# nrf7140_wificore register map
Vendor: Nordic Semiconductor; Series: nRF71; File version: 1
Registers are 32-bit, read-write, reset 0x0 unless marked. A register's access mark holds for its fields unless they carry their own. Offsets are from the block's base; [hi:lo] are bit positions; lines under a group give offsets from that group; {n}, {i} and the like mark numbered series.

## RPUPHY (part 4 of 8) — WIFICore RPU PHY peripherals
Base 0x48080000; alternate view of RPUMAC
0xA000 WLAN_AGC group — Unspecified
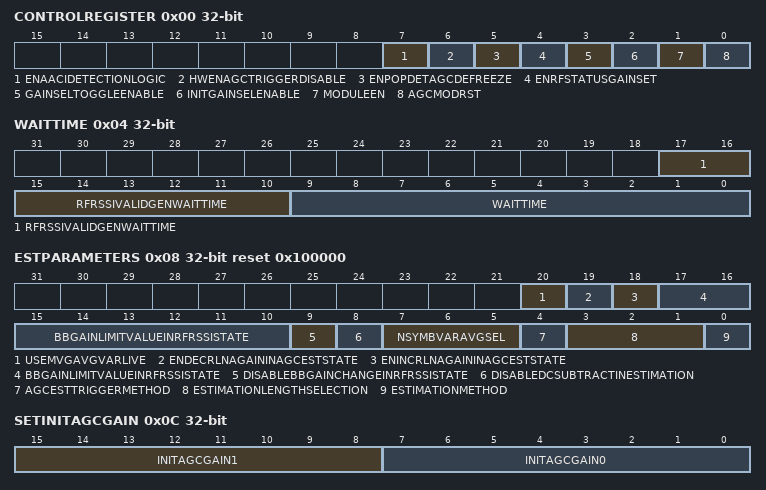
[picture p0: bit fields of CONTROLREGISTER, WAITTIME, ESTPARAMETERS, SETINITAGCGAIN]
  0x00 CONTROLREGISTER — WLAN AGC CONTROL REGISTER
    [7] ENAACIDETECTIONLOGIC — If Flag sets to 1, enables the AACI detection logic. '0' - AACI detection logic is disabled.
    [6] HWENAGCTRIGGERDISABLE — To assert AGC_TRIGGER_DISABLE through ED hardware. When ED is done then immediately AGC module is frozen to stop any further AGC updates. AGC module is released when ED module is reset.
    [5] ENPOPDETAGCDEFREEZE — If Flag set to 1, then it allows to clear the AGC Trigger Disable flag when POP Event comes
    [4] ENRFSTATUSGAINSET — Bit to enable Gain Changes due to RF RSSI STATUS.1-Enable0-Disable
    [3] GAINSELTOGGLEENABLE — Bit to enable registering of changes in Gain Selection.0-Disable1-Enable
    [2] INITGAINSELENABLE — Bit to enable initial AGC gain selection.01
    [1] MODULEEN — Bit field to enable AGC module. 1-enable, 0-disable
    [0] AGCMODRST — Bit to reset the AGC process.
  0x04 WAITTIME — WLAN AGC WAIT TIME
    [17:10] RFRSSIVALIDGENWAITTIME — This value indicates the number of valid samples we need to wait( for the settling of LNA ) to regenerate and read RF RSSI valid.the RSSI valid will be used in RF RSSI STATUS state in AGC fsm.
    [9:0] WAITTIME — The number of cycles after which the final enable will be given to the module once the module enable is asserted high.
  0x08 ESTPARAMETERS reset 0x100000 — WLAN AGC EST PARAMETERS
    [20] USEMVGAVGVARLIVE — This bit when made '1' will enable the moving averager which averages the latest N values of individual variance estimates and also connect the corresponding dB value to the AGC live variance output ports and status registers. The port output will be used by the ED module for ACI detection.When this bit is '0', the moving averager is disabled and the variance estimate is sent out as live variance on the ports and status registers.
    [19] ENDECRLNAGAININAGCESTSTATE — This bit set to '1' will enable the logic that generates DECR request to LNA gain controller. '0' will disable the generation of DECR. This is applicable to both internal 3-bit RF RSSI LNA gain control mode and SLGC mode.
    [18] ENINCRLNAGAININAGCESTSTATE — This bit set to '1' will enable the logic that generates INCR request to LNA gain controller. '0' will disable the generation of INCR. This is applicable to both internal 3-bit RF RSSI LNA gain control mode and SLGC mode.
    [17:10] BBGAINLIMITVALUEINRFRSSISTATE — This value is used to limit the allowed base band gain increment, when LNA gain is reduced ( stage changed )in RF RSSI STATE due to compression signal.
    [9] DISABLEBBGAINCHANGEINRFRSSISTATE — This bit is used either to allow or disallow the base band gain increment, when LNA gain is reduced ( stage changed )in RF RSSI STATE due to compression signal.
    [8] DISABLEDCSUBTRACTINESTIMATION — Flag to disable or enable DC subtraction ( | E[X] |^2 ) while estimating the variance which is used to compute the gain.
    [7:5] NSYMBVARAVGSEL — Number of symbol over which variance is averaged to use in AGC trigger condition:0: 1 symbol1: 2 symbols2: 4 symbols3: 8 symbols4: 16 symbolsEach symbol constitutes number of samples defined in (ESTIMATION_LENGTH_SELECTION)
    [4] AGCESTTRIGGERMETHOD — Defines trigger method used in AGC:
      0=AGC estimation process starts only after ED Done; 1=AGC is free running and starts adjusting the gain value if the absolute difference in RSSI (variance) and target value is not within the limits of lower and upper threshold or if clip count is more than certain threshold
    [3:1] ESTIMATIONLENGTHSELECTION — Estimation window length selection0-8samples,1-16 samples,2-32 samples, 3-64 samples, 4-128 samples, 5-256samples, 6-512 samples
    [0] ESTIMATIONMETHOD — 0: Variance based estimation, 1: Peak based estimation
  0x0C SETINITAGCGAIN — WLAN AGC SET INIT AGC GAIN
    [15:8] INITAGCGAIN1 — 2's complement of the value is considered for this field. So the range is from -128 to 127dB.
    [7:0] INITAGCGAIN0 — Register for setting the initial AGC gain.2's complement of the value is considered for the field. So the range is from -128 to 127dB.
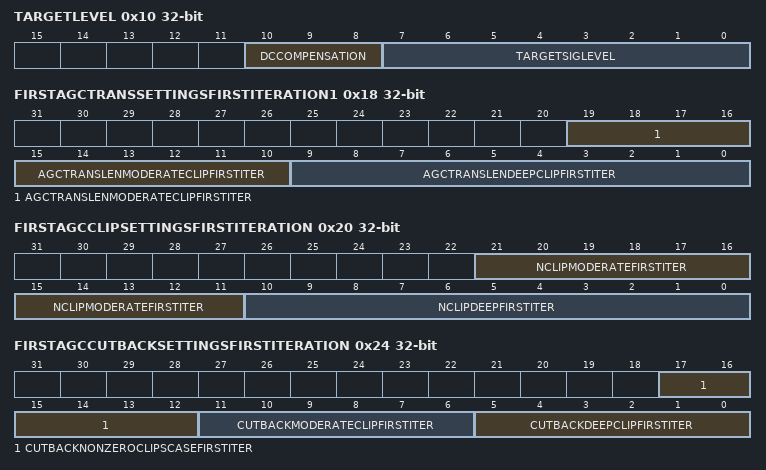
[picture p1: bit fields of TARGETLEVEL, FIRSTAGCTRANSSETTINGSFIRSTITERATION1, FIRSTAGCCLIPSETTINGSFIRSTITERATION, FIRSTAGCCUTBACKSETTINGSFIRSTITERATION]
  0x10 TARGETLEVEL — WLAN AGC TARGET LEVEL
    [10:8] DCCOMPENSATION — DC head room in steps of 1dB.
    [7:0] TARGETSIGLEVEL — AGC target signal level in dB to which the gain need to be adjusted. Input to the field is given in 2's complement form. This can take values between -128dB and 127dB.
  0x14 CLIPLEVEL — WLAN AGC CLIP LEVEL
    [9:0] CLIPLEVEL — The maximum value of ADC output beyond which clip is declared. This maximum value setting is valid for both I and Q samples at the output of ADC.
  0x18 FIRSTAGCTRANSSETTINGSFIRSTITERATION1 — WLAN AGC FIRSTAGC TRANS SETTINGS FIRST ITERATION1
    [19:10] AGCTRANSLENMODERATECLIPFIRSTITER — AGC transient length that is used after applying the AGC cutback when moderate clip conidition is observed.
    [9:0] AGCTRANSLENDEEPCLIPFIRSTITER — AGC transient length to be used after applying the AGC cutback when deep clip conidition is observed.
  0x1C FIRSTAGCTRANSSETTINGSFIRSTITERATION2 — WLAN AGC FIRSTAGC TRANS SETTINGS FIRST ITERATION2
    [9:0] AGCTRANSLENNONZEROCLIPSCASEFIRSTITER — A 10-bit value indicating the length in number of samples to skip for the AGC transient to settle.
  0x20 FIRSTAGCCLIPSETTINGSFIRSTITERATION — WLAN AGC FIRSTAGC CLIP SETTINGS FIRST ITERATION
    [21:11] NCLIPMODERATEFIRSTITER — Number of samples in clip to determine moderate clip.
    [10:0] NCLIPDEEPFIRSTITER — Number of samples in clip to decide as deep clip condition.
  0x24 FIRSTAGCCUTBACKSETTINGSFIRSTITERATION — WLAN AGC FIRSTAGC CUTBACK SETTINGS FIRST ITERATION
    [17:12] CUTBACKNONZEROCLIPSCASEFIRSTITER — The cutback to be applied when non-zero number of clips are seen in a symbol and less than the threshold required to call it a moderate clip. Value is considered in 2's complement and can range from -31 to 32 dB.
    [11:6] CUTBACKMODERATECLIPFIRSTITER — Cut back in case of Moderate saturation. The cutback can be anywhere in between 0 to 63dB.
    [5:0] CUTBACKDEEPCLIPFIRSTITER — AGC Cut back in case of Deep saturation.value can be in between 0 to 63dB.
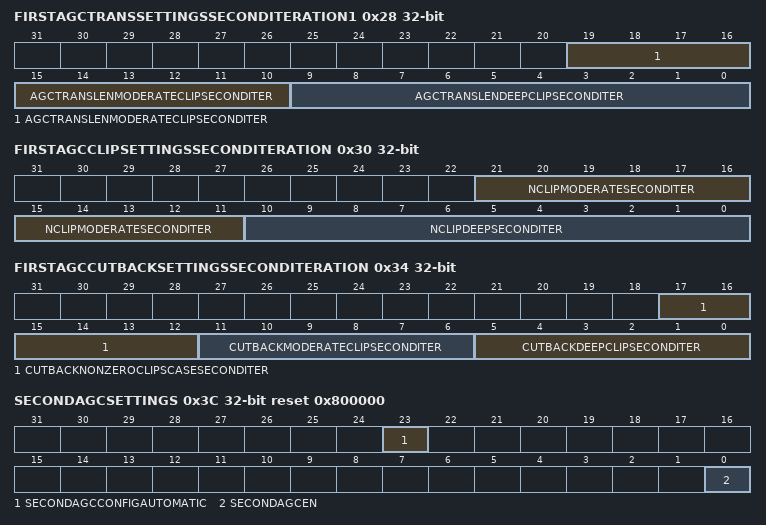
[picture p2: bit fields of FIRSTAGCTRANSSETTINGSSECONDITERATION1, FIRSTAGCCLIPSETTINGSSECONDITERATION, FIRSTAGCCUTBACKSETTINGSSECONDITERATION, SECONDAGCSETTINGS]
  0x28 FIRSTAGCTRANSSETTINGSSECONDITERATION1 — WLAN AGC FIRSTAGC TRANS SETTINGS SECOND ITERATION1
    [19:10] AGCTRANSLENMODERATECLIPSECONDITER — AGC transient length that is used after applying the AGC cutback when moderate clip conidition is observed in second iteration.
    [9:0] AGCTRANSLENDEEPCLIPSECONDITER — AGC transient length to be used after applying the AGC cutback when deep clip conidition is observed in second iteration.
  0x2C FIRSTAGCTRANSSETTINGSSECONDITERATION2 — WLAN AGC FIRSTAGC TRANS SETTINGS SECOND ITERATION2
    [9:0] AGCTRANSLENNONZEROCLIPSCASESECONDITER — A 10-bit value indicating the length in number of samples to skip for the AGC transient to settle.
  0x30 FIRSTAGCCLIPSETTINGSSECONDITERATION — WLAN AGC FIRSTAGC CLIP SETTINGS SECOND ITERATION
    [21:11] NCLIPMODERATESECONDITER — Number of samples in clip to determine moderate clip. This field can have values from 0 to 512.
    [10:0] NCLIPDEEPSECONDITER — Number of clips to determine as deep saturation.
  0x34 FIRSTAGCCUTBACKSETTINGSSECONDITERATION — WLAN AGC FIRSTAGC CUTBACK SETTINGS SECOND ITERATION
    [17:12] CUTBACKNONZEROCLIPSCASESECONDITER — Amount of cutback to be applied when non-zero number of clips less than the number for Moderate clip are seen in a symbol.Can range from -32 to 31dB
    [11:6] CUTBACKMODERATECLIPSECONDITER — Cut back in case of Moderate saturation. Any value in between 0 and 63dB can be provided.
    [5:0] CUTBACKDEEPCLIPSECONDITER — AGC Cut back in case of Deep saturation.Cutback can be any value in between 0 and 63dB.
  0x38 FIRSTAGCFINALTRANSIENTLEN — WLAN AGC FIRSTAGC FINAL TRANSIENT LEN
    [9:0] AGCTRANSIENTLENFINALFIRSTAGCEST — Transient length in number of cycles which will be given at the end of estimation while estimating AGC.
  0x3C SECONDAGCSETTINGS reset 0x800000 — WLAN AGC SECONDAGC SETTINGS
    [23] SECONDAGCCONFIGAUTOMATIC — Enable automatic configuration of the second AGC:
      0=Second AGC control based on registers; 1=Second AGC is controlled by the receiver training mode (SECOND_AGC_EN register is overwritten)
    [0] SECONDAGCEN — The counter starts decrementing only when this bit field is set to 1.
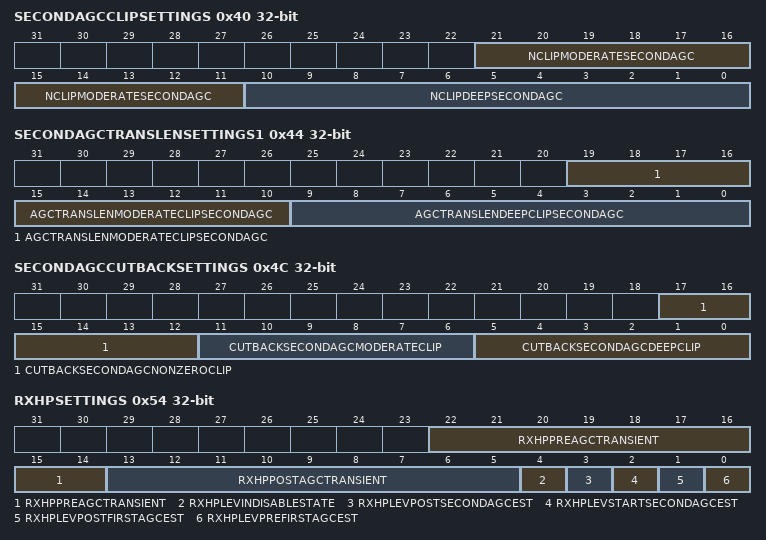
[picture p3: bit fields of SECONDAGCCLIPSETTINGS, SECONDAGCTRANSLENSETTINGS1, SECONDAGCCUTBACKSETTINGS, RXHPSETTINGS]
  0x40 SECONDAGCCLIPSETTINGS — WLAN AGC SECONDAGC CLIP SETTINGS
    [21:11] NCLIPMODERATESECONDAGC — The minimum number of clips, less than in number for deep clip, beyond which decision about moderate clip condition is made.
    [10:0] NCLIPDEEPSECONDAGC — Minimum Number of clips to decide the occurence of deep saturation.
  0x44 SECONDAGCTRANSLENSETTINGS1 — WLAN AGC SECONDAGC TRANS LEN SETTINGS1
    [19:10] AGCTRANSLENMODERATECLIPSECONDAGC — Transient length to be considered when moderate clip is observed.
    [9:0] AGCTRANSLENDEEPCLIPSECONDAGC — AGC transient length in case of deep clip during second AGC estimation.
  0x48 SECONDAGCTRANSLENSETTINGS2 — WLAN AGC SECONDAGC TRANS LEN SETTINGS2
    [9:0] AGCTRANSLENNONZEROCLIPSCASESECONDAGC — AGC transient length when non zero number of clips are seen in a symbol.
  0x4C SECONDAGCCUTBACKSETTINGS — WLAN AGC SECONDAGC CUTBACK SETTINGS
    [17:12] CUTBACKSECONDAGCNONZEROCLIP — Cutback to be applied when non zero number of clips are seen. Range is -32 to 31dB.
    [11:6] CUTBACKSECONDAGCMODERATECLIP — The amount of AGC gain cutback to be applied when the number of clips observed satisfy the condition for deciding moderate saturation condition. Range is 0 to 63dB.
    [5:0] CUTBACKSECONDAGCDEEPCLIP — AGC cutback to be applied when deep saturation case is observed.Range is 0 to 63dB.
  0x50 SECONDAGCFINALTRANSIENTLEN — WLAN AGC SECONDAGC FINAL TRANSIENT LEN
    [9:0] AGCTRANSIENTLENFINALSECONDAGCEST — final transient to be applied while fine tuning the AGC estimation for the second time.
  0x54 RXHPSETTINGS — WLAN AGC RXHP SETTINGS
    [22:14] RXHPPREAGCTRANSIENT — Transient length in number of data samples before switching level of RXHP before starting next AGC estimation.
    [13:5] RXHPPOSTAGCTRANSIENT — Transient length in number of data samples before switching level of RXHP after a particular event (after applying final AGC value)
    [4] RXHPLEVINDISABLESTATE — Level of the RXHP signal when module is disabled.
    [3] RXHPLEVPOSTSECONDAGCEST — RXHP level applied to RF after second stage AGC estimation
    [2] RXHPLEVSTARTSECONDAGCEST — RXHP level applied to at the start of second stage AGC estimation.
    [1] RXHPLEVPOSTFIRSTAGCEST — RXHP level applied to RF post AGC estimation but before last AGC transient completed
    [0] RXHPLEVPREFIRSTAGCEST — RXHP level before AGC estimation is completed. This is the level since AGC module is enabled till AGC estimation is completed
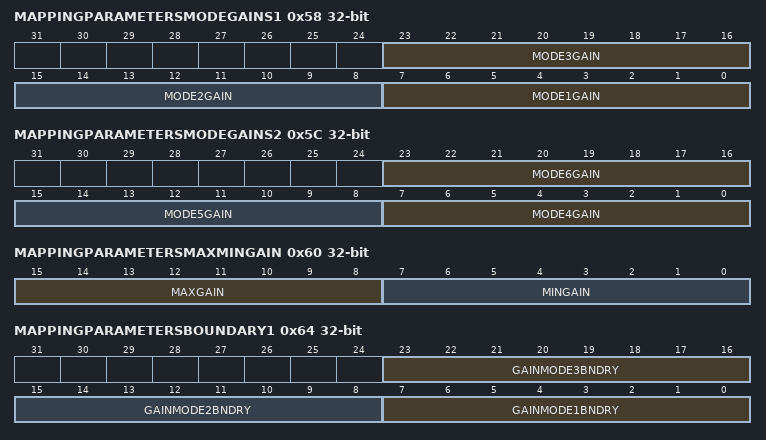
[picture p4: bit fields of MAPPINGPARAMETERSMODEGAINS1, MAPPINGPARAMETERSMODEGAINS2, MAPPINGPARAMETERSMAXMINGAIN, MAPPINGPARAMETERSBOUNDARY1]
  0x58 MAPPINGPARAMETERSMODEGAINS1 — WLAN AGC MAPPING PARAMETERS MODE GAINS1
    [23:16] MODE3GAIN — Gain in MODE3. 2's complement representation. Value ranges between -128 and 127
    [15:8] MODE2GAIN — Gain in MODE1. 2's complement representation. Value ranges between -128 and 127
    [7:0] MODE1GAIN — Gain in MODE1. 2's complement representation. Value ranges between -128 and 127
  0x5C MAPPINGPARAMETERSMODEGAINS2 — WLAN AGC MAPPING PARAMETERS MODE GAINS2
    [23:16] MODE6GAIN — Gain in MODE6. 2's complement representation. Value ranges between -128 and 127
    [15:8] MODE5GAIN — Gain in MODE5. 2's complement representation. Value ranges between -128 and 127
    [7:0] MODE4GAIN — Gain in MODE4. 2's complement representation. Value ranges between -128 and 127
  0x60 MAPPINGPARAMETERSMAXMINGAIN — WLAN AGC MAPPING PARAMETERS MAX MIN GAIN
    [15:8] MAXGAIN — Maximum gain in dB. Maximum gain input to RF. Value ranges between -128 and 127.
    [7:0] MINGAIN — Maximum gain in dB. Maximum gain input to RF. Value ranges between -128 and 127.
  0x64 MAPPINGPARAMETERSBOUNDARY1 — WLAN AGC MAPPING PARAMETERS BOUNDARY1
    [23:16] GAINMODE3BNDRY — GAIN_MODE3_BNDRY (GM3_B)MAX_GAIN > GM5_B >GM4_B >GM3_B > GM2_B > GM1_B > MIN_GAIN
    [15:8] GAINMODE2BNDRY — GAIN-MODE2 boundary (GM2_B)MAX_GAIN > GM5_B >GM4_B >GM3_B > GM2_B > GM1_B > MIN_GAIN
    [7:0] GAINMODE1BNDRY — GAIN-MODE1 boundary (GM1_B)MAX_GAIN > GM5_B >GM4_B >GM3_B > GM2_B > GM1_B > MIN_GAIN
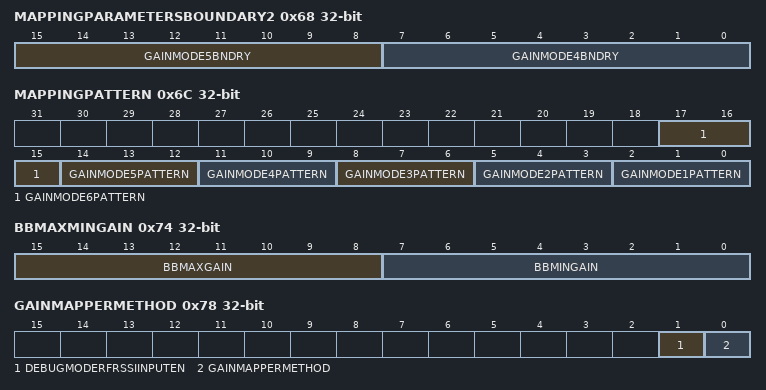
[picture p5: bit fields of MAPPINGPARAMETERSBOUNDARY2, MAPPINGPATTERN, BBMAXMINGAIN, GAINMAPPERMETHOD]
  0x68 MAPPINGPARAMETERSBOUNDARY2 — WLAN AGC MAPPING PARAMETERS BOUNDARY2
    [15:8] GAINMODE5BNDRY — GAIN-MODE5 boundary (GM5_B)MAX_GAIN > GM5_B >GM4_B >GM3_B > GM2_B > GM1_B > MIN_GAIN
    [7:0] GAINMODE4BNDRY — GAIN-MODE4 boundary (GM4_B)MAX_GAIN > GM5_B >GM4_B >GM3_B > GM2_B > GM1_B > MIN_GAIN
  0x6C MAPPINGPATTERN — WLAN AGC MAPPING PATTERN
    [17:15] GAINMODE6PATTERN — Pattern for indicating the gain region between MODE6-GAIN and MAX-GAIN
    [3n-1:3n-3] GAINMODE{n}PATTERN (n=2..5) — Pattern for indicating the gain region between MODE{n}-GAIN and MODE{n+1}-GAIN
    [2:0] GAINMODE1PATTERN — Pattern for indicating the gain region between MIN-GAIN and MODE2-GAIN
  0x70 BBGAINOFFSET — WLAN AGC BB GAIN OFFSET
    [5:0] BBGAINOFFSET — This contains Base-Band Gain Offset value used to adjust the calculated base band gain to make it map properly to VGA
  0x74 BBMAXMINGAIN — WLAN AGC BB MAX MIN GAIN
    [15:8] BBMAXGAIN — This value indicates the Maximum Gain we can set to VGA in Base Band.
    [7:0] BBMINGAIN — This value indicates the Minimum Gain we can set to VGA in Base Band
  0x78 GAINMAPPERMETHOD — WLAN AGC GAIN MAPPER METHOD
    [1] DEBUGMODERFRSSIINPUTEN — This register enables inputting of the RF RSSI Status/Valid from the Debug input register instead of the input ports. This is used for validation of the AGC functinality. Similar to DEBUGIQ mode where IQ's are fed into the SCP module using DEBUG input registers instead of the SCP IQ input ports.
      0=RF RSSI status/Valid from AGC input ports; 1=RF RSSI status/Valid input from Debug register
    [0] GAINMAPPERMETHOD
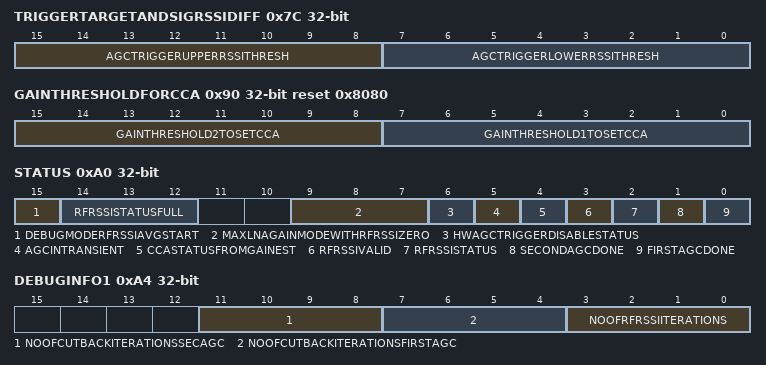
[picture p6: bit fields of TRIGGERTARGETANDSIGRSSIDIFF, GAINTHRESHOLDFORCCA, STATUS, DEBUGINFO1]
  0x7C TRIGGERTARGETANDSIGRSSIDIFF — WLAN AGC TRIGGER TARGET AND SIGRSSI DIFF
    [15:8] AGCTRIGGERUPPERRSSITHRESH — Contains threshold value in dB for triggering AGC gain estimation when AGC is free running. If Computed Variance - Target Variance is greater than 0 and if Abs(Computed_Variance - Target_Variance) is more than threshold.
    [7:0] AGCTRIGGERLOWERRSSITHRESH — contains threshold value in dB for triggering AGC gain estimation when AGC is free running. If Computed Variance - Target Variance is less than 0 and if Abs(Computed_Variance - Target_Variance) is more than threshold.
  0x80 SETINITGAININTRIGGER — WLAN AGC SET INIT GAIN IN TRIGGER
    [0] SETINITGAININTRIGGERSTATE — In method-2 if this flag sets then if agc trigger happens due to decrease in signal power then we will set the gain to initial gain.
  0x84 TRIGGERCLIPTHRESH — WLAN AGC TRIGGER CLIP THRESH
    [10:0] AGCTRIGGERCLIPTHRESH — Number of samples in clip to trigger AGC gain estimation when AGC is free running..
  0x88 TRIGGERDISABLE — WLAN AGC TRIGGER DISABLE
    [0] AGCTRIGGERDISABLE — Disables AGC trigger.
      0=AgcEstimationEnabled; 1=Stop triggering AGC estimation so that the gain value does not change
  0x8C MAXRFRSSISTATUSCOUNT — WLAN AGC MAX RF RSSI STATUS COUNT
    [3:0] MAXNOOFRFRSSIBASEDGAINSET — This value indicates the maximum no of times, we can do RF RSSI status basedgain mapping in RF_RSSI_STATUS_GAIN_SET state in AGC.
  0x90 GAINTHRESHOLDFORCCA reset 0x8080 — WLAN AGC GAIN THRESHOLD FOR CCA
    [15:8] GAINTHRESHOLD2TOSETCCA — Register for setting the gain threshold to compare with estimated gain value and set cca flag. value is2's complement of the value, so the range is from -128 to 127dB.
    [7:0] GAINTHRESHOLD1TOSETCCA — Register for setting the gain threshold to compare with estimated gain value and set cca flag. value is2's complement of the value, so the range is from -128 to 127dB.
  0x94 WAITTIMEAFTERTRIGGER — WLAN AGC WAIT TIME AFTER TRIGGER
    [9:0] WAITTIMEAFTERAGCTRIGGER — this value represents the amount of time we need to wait after AGC trigger and before we go to estimation process. this is needed to avoid AGC estimation on initial ramp of the signal.
  0x98 FINVALMAPPED ro — WLAN AGC FIN VAL MAPPED
    [9:0] MAPPEDAGCVALUE — This represents the AGC value after mapping
  0x9C FINVAL ro — WLAN AGC FIN VAL
    [7:0] AGCFINALVALUE — Register where the final value of the AGC is written.
  0xA0 STATUS — WLAN AGC STATUS
    [15] DEBUGMODERFRSSIAVGSTART — This bit is the output of the internal RF RSSI AVG start signal. The port output is connected to this register, so that it can be used for AGC testing in DEBUG IQ mode.
    [14:12] RFRSSISTATUSFULL — Indicates the status of the RF RSSI. (Returns all 3-bits).
    [9:7] MAXLNAGAINMODEWITHRFRSSIZERO — This register holds the value of the LNA gain mode to which the AGC converged to during the RF RSSI based LNA gain stage setting. This the max LNA gain mode for which average RF RSSI was zero.Note that this value of the LNA gain mode will be different from the final AGC LNA mode, because based on baseband gain constraints (max and min values), we will be forced to choose a different LNA gain mode.
    [6] HWAGCTRIGGERDISABLESTATUS — Hardware Controlled AGC Trigger disable status
    [5] AGCINTRANSIENT — Indicates when AGC is in transient.
    [4] CCASTATUSFROMGAINEST — Generating the status by comparing the Agc Gain with Threshold to represent the channel busy status.Level 'High' indicates channel is busy.
    [3] RFRSSIVALID — Indicates when RF_RSSI_STATUS is holding a valid value. Write any value to this field to acknowledge read and reset it.
    [2] RFRSSISTATUS — Indicates the status of the RF RSSI (Only returns bit 0 used by legacy mode).
    [1] SECONDAGCDONE — Level 'High' indicates second stage AGC is completed.
    [0] FIRSTAGCDONE — Level 'High' indicates first stage AGC is completed.
  0xA4 DEBUGINFO1 ro — WLAN AGC DEBUG INFO1
    [11:8] NOOFCUTBACKITERATIONSSECAGC — stores the value which represents the no of cutback iterations taken in the Sec AGC estimation process.
    [7:4] NOOFCUTBACKITERATIONSFIRSTAGC — stores the value which represents the no of cutback iterations taken in the First AGC estimation process.
    [3:0] NOOFRFRSSIITERATIONS — stores the value which represents the no of rf rssi loops (LNA stage chages )entered in the RF RSSI STATE.
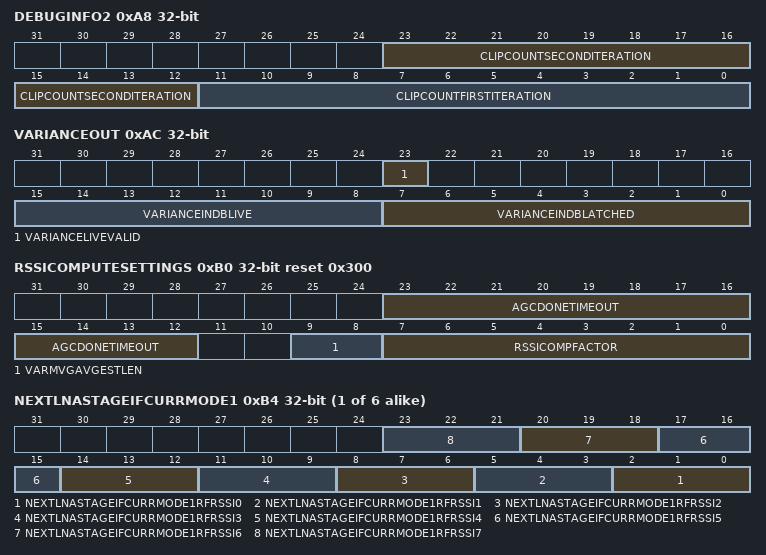
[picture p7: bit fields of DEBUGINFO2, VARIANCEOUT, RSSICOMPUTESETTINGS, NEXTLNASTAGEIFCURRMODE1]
  0xA8 DEBUGINFO2 ro — WLAN AGC DEBUG INFO2
    [23:12] CLIPCOUNTSECONDITERATION — stores the value which represents the no of saturated samples seen in the first cutback iteration.
    [11:0] CLIPCOUNTFIRSTITERATION — stores the value which represents the no of saturated samples seen in the second cutback iteration.
  0xAC VARIANCEOUT ro — WLAN AGC VARIANCE OUT
    [23] VARIANCELIVEVALID — Valid for VARIANCE_IN_DB_LIVE. This will become high after the first update of the live variance. Will become low during module reset or during AGC trigger.
    [15:8] VARIANCEINDBLIVE — This is the free running variance in dB, which is being computed for variance based AGC triggering.
    [7:0] VARIANCEINDBLATCHED — This value is the variance in dB, which was latched during the posedge of EdDone.
  0xB0 RSSICOMPUTESETTINGS reset 0x300 — WLAN AGC RSSI COMPUTE SETTINGS
    [23:12] AGCDONETIMEOUT — Timeout in clock cycles for the rf_rssi_valid after rf_rssi_avg_start is triggered:- if timeout an internal rf_rssi_valid is generated to prevent the FSM to stuck- timeout check is disabled if AGC_DONE_TIMEOUT is set to 0
    [9:8] VARMVGAVGESTLEN — The moving averager that averages the latest N variance estimates. (The moving averaged variance could be given out as free-running Live variance by setting the register configuration). The value of N is selected by this field.0x0 - not used0x1 - N=20x2 - N=40x3 - N=8
    [7:0] RSSICOMPFACTOR — This is a signed value in dB that used in the AGC RSSI computation, from the AGC log variance.AGC_RSSI= (AGC_LOG_VARIANCE - AGC_GAIN_DB) + AGC_RSSI_COMP_FACTOR
  {0xB0+4j} NEXTLNASTAGEIFCURRMODE{j} (j=1..6) — WLAN AGC NEXT LNA STAGE IF CURRMODE{j}
    [3n+2:3n] NEXTLNASTAGEIFCURRMODE{j}RFRSSI{n} (n=0..7) — This register holds the next LNA stage, if the RF RSSI (3-bit) is '{n}'.
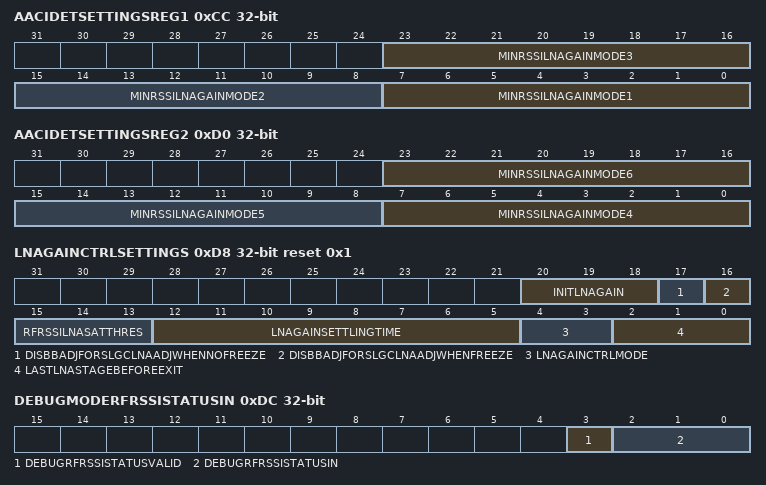
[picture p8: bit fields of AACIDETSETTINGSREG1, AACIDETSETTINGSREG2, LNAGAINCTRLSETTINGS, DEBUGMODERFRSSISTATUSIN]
  0xCC AACIDETSETTINGSREG1 — WLAN AGC AACI DET SETTINGS REG 1
    [23:16] MINRSSILNAGAINMODE3 — This field represents the min rssi for the LNA gain mode 3. If the RSSI of the input signal is below this value, the AGC would never have come to this gain modein the first place. This value is configure from the LNA switch point information.
    [15:8] MINRSSILNAGAINMODE2 — This field represents the min rssi for the LNA gain mode 2. If the RSSI of the input signal is below this value, the AGC would never have come to this gain modein the first place. This value is configure from the LNA switch point information.
    [7:0] MINRSSILNAGAINMODE1 — This field represents the min rssi for the LNA gain mode 1. If the RSSI of the input signal is below this value, the AGC would never have come to this gain modein the first place. This value is configure from the LNA switch point information.
  0xD0 AACIDETSETTINGSREG2 — WLAN AGC AACI DET SETTINGS REG 2
    [23:16] MINRSSILNAGAINMODE6 — This field represents the min rssi for the LNA gain mode 6. If the RSSI of the input signal is below this value, the AGC would never have come to this gain modein the first place. This value is configure from the LNA switch point information.
    [15:8] MINRSSILNAGAINMODE5 — This field represents the min rssi for the LNA gain mode 5. If the RSSI of the input signal is below this value, the AGC would never have come to this gain modein the first place. This value is configure from the LNA switch point information.
    [7:0] MINRSSILNAGAINMODE4 — This field represents the min rssi for the LNA gain mode 4. If the RSSI of the input signal is below this value, the AGC would never have come to this gain modein the first place. This value is configure from the LNA switch point information.
  0xD4 AACIDETTHRESHOLD — WLAN AGC AACI DET THRESHOLD
    [7:0] AACIDETTHRESHOLD — This field represents the threshold in the below equation:if (MIN_RSSI(LNA_GAIN_MODE) - AGC rssi > AACI_DET_THRESHOLD)then, AACI detected in AGC module.Where MIN_RSSI(LNA_GAIN_MODE) is the value in the config register, corresponding to the LNA gain mode at which the AGC converged during the LNA gain search stage. Unsigned value, maximum 127.
  0xD8 LNAGAINCTRLSETTINGS reset 0x1 — WLAN AGC LNA GAIN CTRL SETTINGS
    [20:18] INITLNAGAIN — Setting the initial LNA gain stage. This is 3-bit value, that needs to specify the LNA stage in terms of the original LNA gain stage specification format used by RF.
    [17] DISBBADJFORSLGCLNAADJWHENNOFREEZE — This bit will disable the logic which will trigger BB gain adjust (to keep the total gain constant) when BT trigger has caused an LNA change. This logic sits inside the AGC trigger disable(freeze). This means that when this bit is enabled, when AGC is not in freeze and an external SLGC LNA gain adj start is detected, we'll wait for SLGC LNA gain adj done and if an LNA gain change is detected we'll do a corresponding BB gain change to keep the total gain constant.'0' - BB gain adjust enabled (when LNA gain change detected).'1' - BB gain adjust disabled(when LNA gain change detected).
    [16] DISBBADJFORSLGCLNAADJWHENFREEZE — This bit will disable the logic which will trigger BB gain adjust (to keep the total gain constant) when BT trigger has caused an LNA change. This logic sits outside the AGC trigger disable(freeze).'0' - BB gain adjust enabled (when LNA gain change detected).'1' - BB gain adjust disabled(when LNA gain change detected).
    [15:13] RFRSSILNASATTHRES — This the value of the threshold, equal to or less than which the average RF RSSI Status has to be if the LNA is considered to be not-saturating. Can be any value from 0 to 7.
    [12:5] LNAGAINSETTLINGTIME — This is the duration in terms of ADC sample periods, that we need to wait before issuing start for the RSSI averaging. This wait time allows for the new LNA gain stage to settle down.
    [4:3] LNAGAINCTRLMODE — There are three modes of LNA gain control.'0' - Legacy mode of LNA gain control based on 1 bit RF RSSI via RF controller interface.'1' - New 3-bit RF RSSI + LUT based LNA gain control that directly interfaces with RF.'2' - External LNA gain control using the SLGC module.
    [2:0] LASTLNASTAGEBEFOREEXIT — This register is used only when LUT based LNA mode search is used.This is the LNA stage after reaching which further LNA mode search is aborted. This this the last usable LNA mode. This is used in the case where the RF contains less than 6 LNA stages. If the usable LNA stage values starting from highest to lowest is 4 down to 0, then we have to configure this register to 4.
  0xDC DEBUGMODERFRSSISTATUSIN — WLAN AGC DEBUG MODE RF RSSI STATUS IN
    [3] DEBUGRFRSSISTATUSVALID — This value of RF RSSI valid will be used to bypass the corresponding port value if DEBUG_MODE_RF_RSSI_INPUT_EN is '1'.
    [2:0] DEBUGRFRSSISTATUSIN — This value of 3-bit RF RSSI status will be used to bypass the corresponding port value if DEBUG_MODE_RF_RSSI_INPUT_EN is '1'.
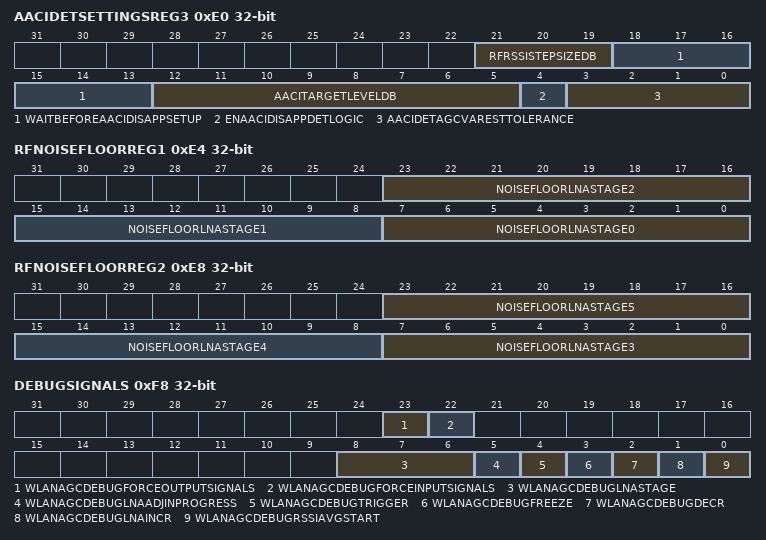
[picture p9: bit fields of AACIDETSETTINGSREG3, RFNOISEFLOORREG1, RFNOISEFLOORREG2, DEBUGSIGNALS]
  0xE0 AACIDETSETTINGSREG3 — WLAN AGC AACI DET SETTINGS REG 3
    [21:19] RFRSSISTEPSIZEDB — The step size in dB of RF RSSI status value. This is used in the equation:LNA_IP_RSSI_EST = MIN_RSSI_LNA_GAIN_MODE + RF_RSSI_AVG**RF_RSSI_STEP_SIZE_DB.RF_RSSI_AVG (= RF_RSSI_STATUS) is the value of RF RSSI value measured with the LNA_GAIN_MODE. The step size is an unsigned value.
    [18:13] WAITBEFOREAACIDISAPPSETUP — Number of symbols (each ESTIMATION_LENGTH duration) that the AGC needs to wait after AACI detection before starting to setup the disappearance logic. For eg. if the ESTIMATION_LENGTH is 0.4us and this reg value is 10, then it waits for 10 symbol ends, equivalent to 4us, before starting the disappearance detection logic. This is used when the AGC is working in external LGC mode when the LNA gain cannot be incremented immediately after trigger as that would interfere with the BT module's packet detection/decoding. This helps in giving the BT module sufficient time to assert freeze.
    [12:5] AACITARGETLEVELDB — This is the target level in dB (max 54dB and min 0dB) that we want the AACI signal to be placed at (in the digital variance domain), when we enable the disappearance trigger logic. This should be set in such a way so as to accomodate inband signals that have power greater than AACI leakage power to be detected, at the same time to keep the variance in dB high enough to detect a fall in variance (indicating disappearance of AACI signal). For example, a value of 30dB will give a head room of 15dB for inband signals to be decoded and still be high enough to indicate disappearance of AACI signal.
    [4] ENAACIDISAPPDETLOGIC — This bit set to '1' enables the logic that sets up the disappearance detection mechanism, so that, when the AACI signal disappears (causing a fall in the AGC RSSI), a AACI_DISAPP_TRIG is generated, which causes AGC re-estimation. By this way, the LNA stage can be returned to the MAX LNA gain stage.
    [3:0] AACIDETAGCVARESTTOLERANCE — This value of 4-bit unsigned is the tolerance in dB of the AGC variance estimation. This is used in the logic that decides when to get out of AACI in progress state. If the live AGC variance in dB is less than the AGC AACI variance - tolerance, this indicates the original signal that triggered AACI detection has disappeared, so the AACI detection FSM will de-assert AACI_Detected and will get out of AACI_IN_PROG_STATE state.
  0xE4 RFNOISEFLOORREG1 — WLAN AGC RF NOISE FLOOR REG 1
    [23:16] NOISEFLOORLNASTAGE2 — This value of 8-bit signed is the noise floor expressed in dBm. Please note this depends on the operating bandwidth so has to be reconfigured when OBW changes.
    [15:8] NOISEFLOORLNASTAGE1 — This value of 8-bit signed is the noise floor expressed in dBm. Please note this depends on the operating bandwidth so has to be reconfigured when OBW changes.
    [7:0] NOISEFLOORLNASTAGE0 — This value of 8-bit signed is the noise floor expressed in dBm. Please note this depends on the operating bandwidth so has to be reconfigured when OBW changes.
  0xE8 RFNOISEFLOORREG2 — WLAN AGC RF NOISE FLOOR REG 2
    [23:16] NOISEFLOORLNASTAGE5 — This value of 8-bit signed is the noise floor expressed in dBm. Please note this depends on the operating bandwidth so has to be reconfigured when OBW changes.
    [15:8] NOISEFLOORLNASTAGE4 — This value of 8-bit signed is the noise floor expressed in dBm. Please note this depends on the operating bandwidth so has to be reconfigured when OBW changes.
    [7:0] NOISEFLOORLNASTAGE3 — This value of 8-bit signed is the noise floor expressed in dBm. Please note this depends on the operating bandwidth so has to be reconfigured when OBW changes.
  0xF8 DEBUGSIGNALS — WLAN AGC DEBUG SIGNALS
    [23] WLANAGCDEBUGFORCEOUTPUTSIGNALS — When set output signals are overriden with the fields below.
    [22] WLANAGCDEBUGFORCEINPUTSIGNALS — When set input and data signals are overriden with the fields below.
    [8:6] WLANAGCDEBUGLNASTAGE — Overridden LNA_STAGE value applicable when WLAN_AGC_DEBUG_FORCE_INPUT_SIGNALS is set.
    [5] WLANAGCDEBUGLNAADJINPROGRESS — Overridden LNA_ADJ_IN_PROGRESS value applicable when WLAN_AGC_DEBUG_FORCE_INPUT_SIGNALS is set.
    [4] WLANAGCDEBUGTRIGGER — Overridden WLAN_TRIGGER value applicable when WLAN_AGC_DEBUG_FORCE_OUTPUT_SIGNALS is set.
    [3] WLANAGCDEBUGFREEZE — Overridden WLAN_FREEZE value applicable when WLAN_AGC_DEBUG_FORCE_OUTPUT_SIGNALS is set.
    [2] WLANAGCDEBUGDECR — Overridden WLAN_DECR value applicable when WLAN_AGC_DEBUG_FORCE_OUTPUT_SIGNALS is set.
    [1] WLANAGCDEBUGLNAINCR — Overridden WLAN_INCR value applicable when WLAN_AGC_DEBUG_FORCE_OUTPUT_SIGNALS is set.
    [0] WLANAGCDEBUGRSSIAVGSTART — Overridden RSSI_AVG_START value applicable when WLAN_AGC_DEBUG_FORCE_OUTPUT_SIGNALS is set.
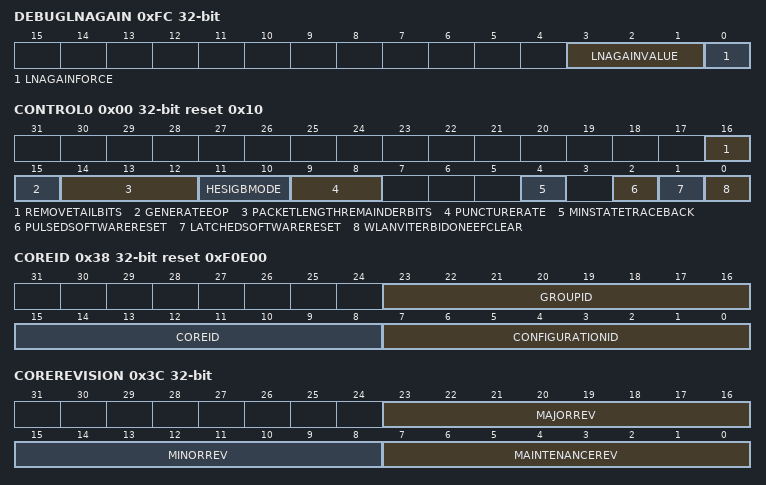
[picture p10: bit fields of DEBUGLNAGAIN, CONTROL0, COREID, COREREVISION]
  0xFC DEBUGLNAGAIN — WLAN AGC DEBUG LNA GAIN
    [3:1] LNAGAINVALUE — Sets value of agc_lna_gain_stage when LNA_GAIN_FORCE is raised.
    [0] LNAGAINFORCE — Enable debug mechanism for forcing agc_lna_gain_stage signal.
0xB000 WLAN_VITERBI group — Unspecified
  0x00 CONTROL0 reset 0x10 — WLAN VITERBI CONTROL0
    [16] REMOVETAILBITS
      0=Output data bytes contain tail bits; 1=TailBitsAreNotOutput
    [15] GENERATEEOP
      0=Don't generate an EOP flag at the end of the packet; 1=Generate an EOP flag at the end of the packet
    [14:12] PACKETLENGTHREMAINDERBITS — PACKET_LENGTH_REMAINDER_BITS Options are
      0=0Bits; 1=1Bit; 2=2Bits; 4=4Bits; 5=5Bits; 6=6Bits; 7=3Bits
    [11:10] HESIGBMODE — HESIGB_MODEOptions are
      0=NormalVhtPacket; 1=HE-SIG-B uncompressed 20/40 MHz ppduBW (18-bit common field, 52-bit User block field); 2=HeSigBUncompressed2 (HE-SIG-B uncompressed 80 MHz ppduBw (27-bit common field, 52-bit User block field)); 3=HE-SIG-B compressed (no common field, 52-bit User block field)
    [9:8] PUNCTURERATE — PUNCTURE_RATEOptions are
      0=Rate12; 1=Rate23; 2=Rate34; 3=Rate56
    [4] MINSTATETRACEBACK
      0=Trace back from zero state; 1=Trace back from minimum state
    [2] PULSEDSOFTWARERESET — 0 : Do nothing1 : Apply a pulsed software resetThis bit is automatically returns to 0
    [1] LATCHEDSOFTWARERESET
      0=RemoveReset; 1=ApplyReset
    [0] WLANVITERBIDONEEFCLEAR — 0 : Do nothing1 : Clear the event flag WLAN_VITERBI_DONE_EF_STATUSThis bit automatically returns to 0
  0x04 CONTROL1 — WLAN VITERBI CONTROL1
    [23:0] PACKETLENGTHBYTES — Packet length in bytes
  0x08 START — WLAN VITERBI START
    [0] VITERBIACTIVE — ACTIVE=0 when the Wi-Fi Vietrbi is idle, and ACTIVE=1 when the Wi-Fi Viterbi is active.When ACTIVE==1, writing to this bit has no effect.When ACTIVE= =0, writing ACTIVE= 1 causes the Wi-Fi Viterbi to start an operation using theparameters set in the registers above.ACTIVE automatically returns to 0 when the Viterbi operation completes after last trace back
  0x14 IPDMATBUSCONTROL — WLAN VITERBI IPDMA TBUS CONTROL
    [20] IPDMATBUSSTALLWHENCOMPLETE — Controls whether TBus write port stalls upstream when the Viterbi job is complete:
      0=Viterbi TBus write port discards data when the Viterbi job is complete; 1=ViterbiTbusWritePort1 (Viterbi TBus write port stalls upstream when the Viterbi job is complete)
  0x34 STATUS ro — WLAN VITERBI STATUS
    [0] WLANVITERBIDONEEFSTATUS — WLAN_VITERBI_DONE_EF_STATUS is set to 1 when an VITERBI operation completes,and is cleared when 1 is written to WLAN_VITERBI_DONE_EF_CLEAR in the WLAN_VITERBI_CONTROL0 register.
  0x38 COREID ro reset 0xF0E00 — WLAN VITERBI CORE ID
    [23:16] GROUPID — Identifies core as part of an IMG IP family group. [0x0F = UCC]
    [15:8] COREID — Identifies the member of the IP group. [0x0E = Wireless LAN Viterbi]
    [7:0] CONFIGURATIONID — Configuration of the core.
  0x3C COREREVISION ro — WLAN VITERBI CORE REVISION
    [23:16] MAJORREV — Family Major Release Revision.
    [15:8] MINORREV — Core Minor Release Revision.
    [7:0] MAINTENANCEREV — Maintenance Release Revision.
